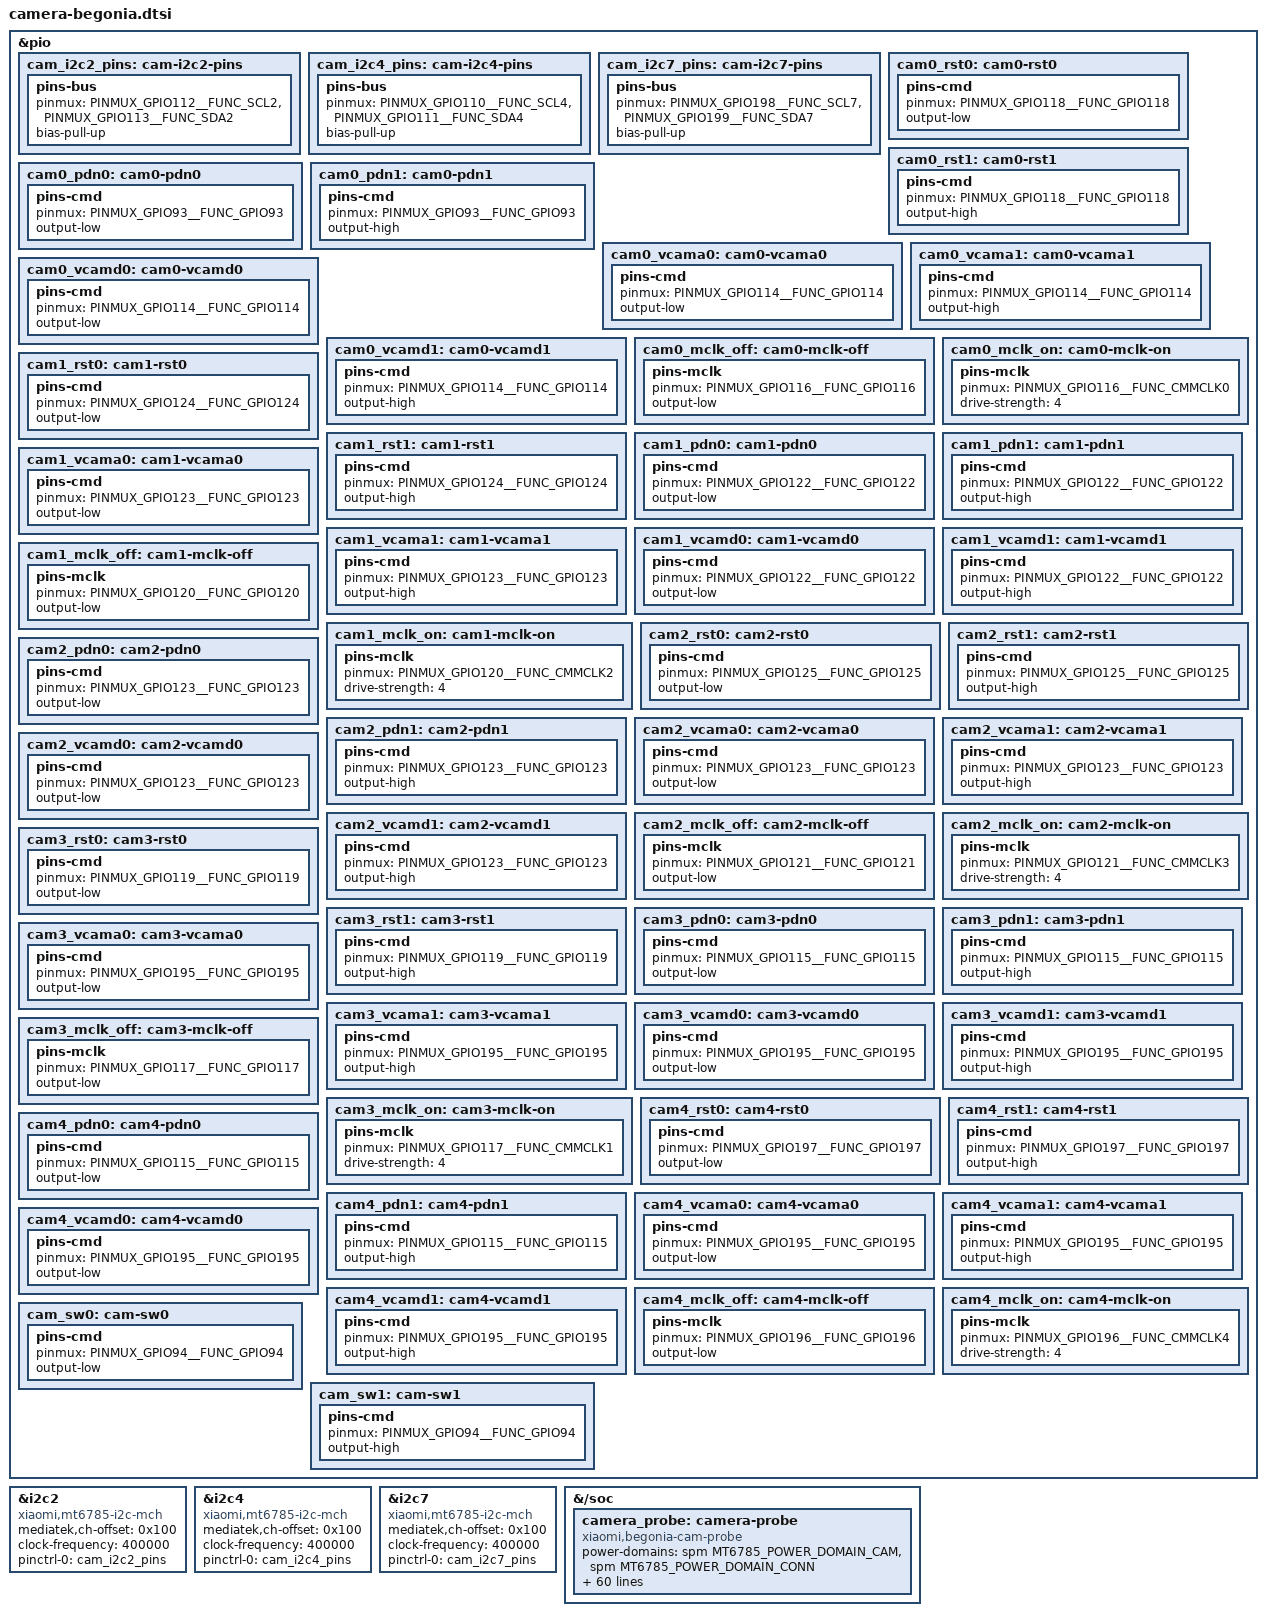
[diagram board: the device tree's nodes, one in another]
// SPDX-License-Identifier: GPL-2.0
/*
 * EXPERIMENTAL (M0): Redmi Note 8 Pro (begonia) camera power and the sensor I2C buses.
 * GENERATED by gen-camera-dtsi.py - do not edit by hand. The labels (pio, topckgen, camsys, spm, i2c2/4/7,
 * camvcamio) are placed by make-cam-dtb.sh.
 */

#include <dt-bindings/power/mediatek,mt6785-power.h>
#include <dt-bindings/clock/mediatek,mt6785-clk.h>
#include <dt-bindings/pinctrl/mediatek,mt6785-pinfunc.h>
#include <dt-bindings/gpio/gpio.h>

&pio {
	cam_i2c2_pins: cam-i2c2-pins {
		pins-bus {
			pinmux = <PINMUX_GPIO112__FUNC_SCL2>,
				 <PINMUX_GPIO113__FUNC_SDA2>;
			bias-pull-up;
		};
	};

	cam_i2c4_pins: cam-i2c4-pins {
		pins-bus {
			pinmux = <PINMUX_GPIO110__FUNC_SCL4>,
				 <PINMUX_GPIO111__FUNC_SDA4>;
			bias-pull-up;
		};
	};

	cam_i2c7_pins: cam-i2c7-pins {
		pins-bus {
			pinmux = <PINMUX_GPIO198__FUNC_SCL7>,
				 <PINMUX_GPIO199__FUNC_SDA7>;
			bias-pull-up;
		};
	};

	cam0_rst0: cam0-rst0 {
		pins-cmd {
			pinmux = <PINMUX_GPIO118__FUNC_GPIO118>;
			output-low;
		};
	};
	cam0_rst1: cam0-rst1 {
		pins-cmd {
			pinmux = <PINMUX_GPIO118__FUNC_GPIO118>;
			output-high;
		};
	};
	cam0_pdn0: cam0-pdn0 {
		pins-cmd {
			pinmux = <PINMUX_GPIO93__FUNC_GPIO93>;
			output-low;
		};
	};
	cam0_pdn1: cam0-pdn1 {
		pins-cmd {
			pinmux = <PINMUX_GPIO93__FUNC_GPIO93>;
			output-high;
		};
	};
	cam0_vcama0: cam0-vcama0 {
		pins-cmd {
			pinmux = <PINMUX_GPIO114__FUNC_GPIO114>;
			output-low;
		};
	};
	cam0_vcama1: cam0-vcama1 {
		pins-cmd {
			pinmux = <PINMUX_GPIO114__FUNC_GPIO114>;
			output-high;
		};
	};
	cam0_vcamd0: cam0-vcamd0 {
		pins-cmd {
			pinmux = <PINMUX_GPIO114__FUNC_GPIO114>;
			output-low;
		};
	};
	cam0_vcamd1: cam0-vcamd1 {
		pins-cmd {
			pinmux = <PINMUX_GPIO114__FUNC_GPIO114>;
			output-high;
		};
	};
	cam0_mclk_off: cam0-mclk-off {
		pins-mclk {
			pinmux = <PINMUX_GPIO116__FUNC_GPIO116>;
			output-low;
		};
	};
	cam0_mclk_on: cam0-mclk-on {
		pins-mclk {
			pinmux = <PINMUX_GPIO116__FUNC_CMMCLK0>;
			drive-strength = <4>;  /* mA (mainline: 2..16 step 2); the raw vendor 1 = 4 mA */
		};
	};

	cam1_rst0: cam1-rst0 {
		pins-cmd {
			pinmux = <PINMUX_GPIO124__FUNC_GPIO124>;
			output-low;
		};
	};
	cam1_rst1: cam1-rst1 {
		pins-cmd {
			pinmux = <PINMUX_GPIO124__FUNC_GPIO124>;
			output-high;
		};
	};
	cam1_pdn0: cam1-pdn0 {
		pins-cmd {
			pinmux = <PINMUX_GPIO122__FUNC_GPIO122>;
			output-low;
		};
	};
	cam1_pdn1: cam1-pdn1 {
		pins-cmd {
			pinmux = <PINMUX_GPIO122__FUNC_GPIO122>;
			output-high;
		};
	};
	cam1_vcama0: cam1-vcama0 {
		pins-cmd {
			pinmux = <PINMUX_GPIO123__FUNC_GPIO123>;
			output-low;
		};
	};
	cam1_vcama1: cam1-vcama1 {
		pins-cmd {
			pinmux = <PINMUX_GPIO123__FUNC_GPIO123>;
			output-high;
		};
	};
	cam1_vcamd0: cam1-vcamd0 {
		pins-cmd {
			pinmux = <PINMUX_GPIO122__FUNC_GPIO122>;
			output-low;
		};
	};
	cam1_vcamd1: cam1-vcamd1 {
		pins-cmd {
			pinmux = <PINMUX_GPIO122__FUNC_GPIO122>;
			output-high;
		};
	};
	cam1_mclk_off: cam1-mclk-off {
		pins-mclk {
			pinmux = <PINMUX_GPIO120__FUNC_GPIO120>;
			output-low;
		};
	};
	cam1_mclk_on: cam1-mclk-on {
		pins-mclk {
			pinmux = <PINMUX_GPIO120__FUNC_CMMCLK2>;
			drive-strength = <4>;  /* mA (mainline: 2..16 step 2); the raw vendor 1 = 4 mA */
		};
	};

	cam2_rst0: cam2-rst0 {
		pins-cmd {
			pinmux = <PINMUX_GPIO125__FUNC_GPIO125>;
			output-low;
		};
	};
	cam2_rst1: cam2-rst1 {
		pins-cmd {
			pinmux = <PINMUX_GPIO125__FUNC_GPIO125>;
			output-high;
		};
	};
	cam2_pdn0: cam2-pdn0 {
		pins-cmd {
			pinmux = <PINMUX_GPIO123__FUNC_GPIO123>;
			output-low;
		};
	};
	cam2_pdn1: cam2-pdn1 {
		pins-cmd {
			pinmux = <PINMUX_GPIO123__FUNC_GPIO123>;
			output-high;
		};
	};
	cam2_vcama0: cam2-vcama0 {
		pins-cmd {
			pinmux = <PINMUX_GPIO123__FUNC_GPIO123>;
			output-low;
		};
	};
	cam2_vcama1: cam2-vcama1 {
		pins-cmd {
			pinmux = <PINMUX_GPIO123__FUNC_GPIO123>;
			output-high;
		};
	};
	cam2_vcamd0: cam2-vcamd0 {
		pins-cmd {
			pinmux = <PINMUX_GPIO123__FUNC_GPIO123>;
			output-low;
		};
	};
	cam2_vcamd1: cam2-vcamd1 {
		pins-cmd {
			pinmux = <PINMUX_GPIO123__FUNC_GPIO123>;
			output-high;
		};
	};
	cam2_mclk_off: cam2-mclk-off {
		pins-mclk {
			pinmux = <PINMUX_GPIO121__FUNC_GPIO121>;
			output-low;
		};
	};
	cam2_mclk_on: cam2-mclk-on {
		pins-mclk {
			pinmux = <PINMUX_GPIO121__FUNC_CMMCLK3>;
			drive-strength = <4>;  /* mA (mainline: 2..16 step 2); the raw vendor 1 = 4 mA */
		};
	};

	cam3_rst0: cam3-rst0 {
		pins-cmd {
			pinmux = <PINMUX_GPIO119__FUNC_GPIO119>;
			output-low;
		};
	};
	cam3_rst1: cam3-rst1 {
		pins-cmd {
			pinmux = <PINMUX_GPIO119__FUNC_GPIO119>;
			output-high;
		};
	};
	cam3_pdn0: cam3-pdn0 {
		pins-cmd {
			pinmux = <PINMUX_GPIO115__FUNC_GPIO115>;
			output-low;
		};
	};
	cam3_pdn1: cam3-pdn1 {
		pins-cmd {
			pinmux = <PINMUX_GPIO115__FUNC_GPIO115>;
			output-high;
		};
	};
	cam3_vcama0: cam3-vcama0 {
		pins-cmd {
			pinmux = <PINMUX_GPIO195__FUNC_GPIO195>;
			output-low;
		};
	};
	cam3_vcama1: cam3-vcama1 {
		pins-cmd {
			pinmux = <PINMUX_GPIO195__FUNC_GPIO195>;
			output-high;
		};
	};
	cam3_vcamd0: cam3-vcamd0 {
		pins-cmd {
			pinmux = <PINMUX_GPIO195__FUNC_GPIO195>;
			output-low;
		};
	};
	cam3_vcamd1: cam3-vcamd1 {
		pins-cmd {
			pinmux = <PINMUX_GPIO195__FUNC_GPIO195>;
			output-high;
		};
	};
	cam3_mclk_off: cam3-mclk-off {
		pins-mclk {
			pinmux = <PINMUX_GPIO117__FUNC_GPIO117>;
			output-low;
		};
	};
	cam3_mclk_on: cam3-mclk-on {
		pins-mclk {
			pinmux = <PINMUX_GPIO117__FUNC_CMMCLK1>;
			drive-strength = <4>;  /* mA (mainline: 2..16 step 2); the raw vendor 1 = 4 mA */
		};
	};

	cam4_rst0: cam4-rst0 {
		pins-cmd {
			pinmux = <PINMUX_GPIO197__FUNC_GPIO197>;
			output-low;
		};
	};
	cam4_rst1: cam4-rst1 {
		pins-cmd {
			pinmux = <PINMUX_GPIO197__FUNC_GPIO197>;
			output-high;
		};
	};
	cam4_pdn0: cam4-pdn0 {
		pins-cmd {
			pinmux = <PINMUX_GPIO115__FUNC_GPIO115>;
			output-low;
		};
	};
	cam4_pdn1: cam4-pdn1 {
		pins-cmd {
			pinmux = <PINMUX_GPIO115__FUNC_GPIO115>;
			output-high;
		};
	};
	cam4_vcama0: cam4-vcama0 {
		pins-cmd {
			pinmux = <PINMUX_GPIO195__FUNC_GPIO195>;
			output-low;
		};
	};
	cam4_vcama1: cam4-vcama1 {
		pins-cmd {
			pinmux = <PINMUX_GPIO195__FUNC_GPIO195>;
			output-high;
		};
	};
	cam4_vcamd0: cam4-vcamd0 {
		pins-cmd {
			pinmux = <PINMUX_GPIO195__FUNC_GPIO195>;
			output-low;
		};
	};
	cam4_vcamd1: cam4-vcamd1 {
		pins-cmd {
			pinmux = <PINMUX_GPIO195__FUNC_GPIO195>;
			output-high;
		};
	};
	cam4_mclk_off: cam4-mclk-off {
		pins-mclk {
			pinmux = <PINMUX_GPIO196__FUNC_GPIO196>;
			output-low;
		};
	};
	cam4_mclk_on: cam4-mclk-on {
		pins-mclk {
			pinmux = <PINMUX_GPIO196__FUNC_CMMCLK4>;
			drive-strength = <4>;  /* mA (mainline: 2..16 step 2); the raw vendor 1 = 4 mA */
		};
	};

	cam_sw0: cam-sw0 {
		pins-cmd {
			pinmux = <PINMUX_GPIO94__FUNC_GPIO94>;
			output-low;
		};
	};
	cam_sw1: cam-sw1 {
		pins-cmd {
			pinmux = <PINMUX_GPIO94__FUNC_GPIO94>;
			output-high;
		};
	};
};

&i2c2 {
	compatible = "xiaomi,mt6785-i2c-mch";
	mediatek,ch-offset = <0x100>;
	clock-frequency = <400000>;
	pinctrl-names = "default";
	pinctrl-0 = <&cam_i2c2_pins>;
	status = "okay";
};

&i2c4 {
	compatible = "xiaomi,mt6785-i2c-mch";
	mediatek,ch-offset = <0x100>;
	clock-frequency = <400000>;
	pinctrl-names = "default";
	pinctrl-0 = <&cam_i2c4_pins>;
	status = "okay";
};

&i2c7 {
	compatible = "xiaomi,mt6785-i2c-mch";
	mediatek,ch-offset = <0x100>;
	clock-frequency = <400000>;
	pinctrl-names = "default";
	pinctrl-0 = <&cam_i2c7_pins>;
	status = "okay";
};

&{/soc} {
	camera_probe: camera-probe {
		compatible = "xiaomi,begonia-cam-probe";
		/* TWO domains on purpose (like md-bringup): otherwise the kernel turns cam on at bind. The driver attaches cam itself. */
		power-domains = <&spm MT6785_POWER_DOMAIN_CAM>, <&spm MT6785_POWER_DOMAIN_CONN>;
		power-domain-names = "cam", "conn";
		clocks = <&topckgen CLK_TOP_CAMTG1>, <&topckgen CLK_TOP_CAMTG2>,
			 <&topckgen CLK_TOP_CAMTG3>, <&topckgen CLK_TOP_CAMTG4>,
			 <&topckgen CLK_TOP_CAMTG5>,
			 <&topckgen CLK_TOP_UNIVPLL_192M_D8>,
			 <&camsys CLK_CAM_TG>;
		clock-names = "tg0", "tg1", "tg2", "tg3", "tg4", "src24", "camtg";
		vcamio-supply = <&camvcamio>;
		pinctrl-names =
			"cam0_rst0",
			"cam0_rst1",
			"cam0_pdn0",
			"cam0_pdn1",
			"cam0_vcama0",
			"cam0_vcama1",
			"cam0_vcamd0",
			"cam0_vcamd1",
			"cam0_mclk_off",
			"cam0_mclk_on",
			"cam1_rst0",
			"cam1_rst1",
			"cam1_pdn0",
			"cam1_pdn1",
			"cam1_vcama0",
			"cam1_vcama1",
			"cam1_vcamd0",
			"cam1_vcamd1",
			"cam1_mclk_off",
			"cam1_mclk_on",
			"cam2_rst0",
			"cam2_rst1",
			"cam2_pdn0",
			"cam2_pdn1",
			"cam2_vcama0",
			"cam2_vcama1",
			"cam2_vcamd0",
			"cam2_vcamd1",
			"cam2_mclk_off",
			"cam2_mclk_on",
			"cam3_rst0",
			"cam3_rst1",
			"cam3_pdn0",
			"cam3_pdn1",
			"cam3_vcama0",
			"cam3_vcama1",
			"cam3_vcamd0",
			"cam3_vcamd1",
			"cam3_mclk_off",
			"cam3_mclk_on",
			"cam4_rst0",
			"cam4_rst1",
			"cam4_pdn0",
			"cam4_pdn1",
			"cam4_vcama0",
			"cam4_vcama1",
			"cam4_vcamd0",
			"cam4_vcamd1",
			"cam4_mclk_off",
			"cam4_mclk_on",
			"sw0",
			"sw1";
		pinctrl-0 = <&cam0_rst0>;
		pinctrl-1 = <&cam0_rst1>;
		pinctrl-2 = <&cam0_pdn0>;
		pinctrl-3 = <&cam0_pdn1>;
		pinctrl-4 = <&cam0_vcama0>;
		pinctrl-5 = <&cam0_vcama1>;
		pinctrl-6 = <&cam0_vcamd0>;
		pinctrl-7 = <&cam0_vcamd1>;
		pinctrl-8 = <&cam0_mclk_off>;
		pinctrl-9 = <&cam0_mclk_on>;
		pinctrl-10 = <&cam1_rst0>;
		pinctrl-11 = <&cam1_rst1>;
		pinctrl-12 = <&cam1_pdn0>;
		pinctrl-13 = <&cam1_pdn1>;
		pinctrl-14 = <&cam1_vcama0>;
		pinctrl-15 = <&cam1_vcama1>;
		pinctrl-16 = <&cam1_vcamd0>;
		pinctrl-17 = <&cam1_vcamd1>;
		pinctrl-18 = <&cam1_mclk_off>;
		pinctrl-19 = <&cam1_mclk_on>;
		pinctrl-20 = <&cam2_rst0>;
		pinctrl-21 = <&cam2_rst1>;
		pinctrl-22 = <&cam2_pdn0>;
		pinctrl-23 = <&cam2_pdn1>;
		pinctrl-24 = <&cam2_vcama0>;
		pinctrl-25 = <&cam2_vcama1>;
		pinctrl-26 = <&cam2_vcamd0>;
		pinctrl-27 = <&cam2_vcamd1>;
		pinctrl-28 = <&cam2_mclk_off>;
		pinctrl-29 = <&cam2_mclk_on>;
		pinctrl-30 = <&cam3_rst0>;
		pinctrl-31 = <&cam3_rst1>;
		pinctrl-32 = <&cam3_pdn0>;
		pinctrl-33 = <&cam3_pdn1>;
		pinctrl-34 = <&cam3_vcama0>;
		pinctrl-35 = <&cam3_vcama1>;
		pinctrl-36 = <&cam3_vcamd0>;
		pinctrl-37 = <&cam3_vcamd1>;
		pinctrl-38 = <&cam3_mclk_off>;
		pinctrl-39 = <&cam3_mclk_on>;
		pinctrl-40 = <&cam4_rst0>;
		pinctrl-41 = <&cam4_rst1>;
		pinctrl-42 = <&cam4_pdn0>;
		pinctrl-43 = <&cam4_pdn1>;
		pinctrl-44 = <&cam4_vcama0>;
		pinctrl-45 = <&cam4_vcama1>;
		pinctrl-46 = <&cam4_vcamd0>;
		pinctrl-47 = <&cam4_vcamd1>;
		pinctrl-48 = <&cam4_mclk_off>;
		pinctrl-49 = <&cam4_mclk_on>;
		pinctrl-50 = <&cam_sw0>;
		pinctrl-51 = <&cam_sw1>;
	};
};
